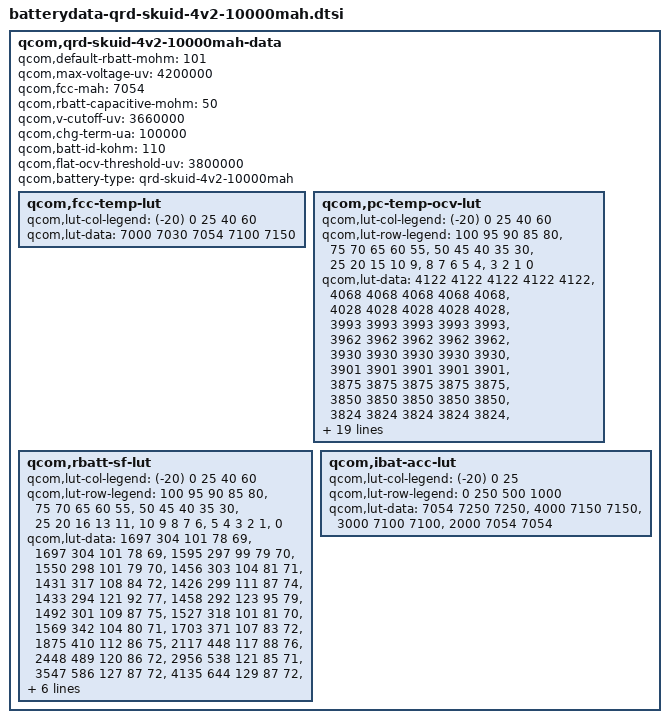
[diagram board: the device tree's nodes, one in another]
/* Copyright (c) 2014, The Linux Foundation. All rights reserved.
 *
 * This program is free software; you can redistribute it and/or modify
 * it under the terms of the GNU General Public License version 2 and
 * only version 2 as published by the Free Software Foundation.
 *
 * This program is distributed in the hope that it will be useful,
 * but WITHOUT ANY WARRANTY; without even the implied warranty of
 * MERCHANTABILITY or FITNESS FOR A PARTICULAR PURPOSE.  See the
 * GNU General Public License for more details.
 * Update from Qualcomm calibation data. 20150508.
 */


qcom,qrd-skuid-4v2-10000mah-data {
	qcom,default-rbatt-mohm = <101>;
	qcom,max-voltage-uv = <4200000>;
	qcom,fcc-mah = <7054>;
	qcom,rbatt-capacitive-mohm = <50>;
	qcom,v-cutoff-uv = <3660000>;
	qcom,chg-term-ua = <100000>;
	qcom,batt-id-kohm = <110>;
	qcom,flat-ocv-threshold-uv = <3800000>;
	qcom,battery-type = "qrd-skuid-4v2-10000mah";

	qcom,fcc-temp-lut {
		qcom,lut-col-legend = <(-20) 0 25 40 60>;
		qcom,lut-data = <7000 7030 7054 7100 7150>;
	};

	qcom,pc-temp-ocv-lut {
		qcom,lut-col-legend = <(-20) 0 25 40 60>;
		qcom,lut-row-legend = <100 95 90 85 80>,
				<75 70 65 60 55>,
				<50 45 40 35 30>,
				<25 20 15 10 9>,
				<8 7 6 5 4>,
				<3 2 1 0>;
		qcom,lut-data = <4122 4122 4122 4122 4122>,
			<4068 4068 4068 4068 4068>,
			<4028 4028 4028 4028 4028>,
			<3993 3993 3993 3993 3993>,
			<3962 3962 3962 3962 3962>,
			<3930 3930 3930 3930 3930>,
			<3901 3901 3901 3901 3901>,
			<3875 3875 3875 3875 3875>,
			<3850 3850 3850 3850 3850>,
			<3824 3824 3824 3824 3824>,
			<3799 3799 3799 3799 3799>,
			<3776 3776 3776 3776 3776>,
			<3755 3755 3755 3755 3755>,
			<3738 3738 3738 3738 3738>,
			<3724 3724 3724 3724 3724>,
			<3711 3711 3711 3711 3711>,
			<3700 3700 3700 3700 3700>,
			<3690 3690 3690 3690 3690>,
			<3681 3681 3681 3681 3681>,
			<3679 3679 3679 3679 3679>,
			<3678 3678 3678 3678 3678>,
			<3676 3676 3676 3676 3676>,
			<3674 3674 3674 3674 3674>,
			<3673 3673 3673 3673 3673>,
			<3671 3671 3671 3671 3671>,
			<3669 3669 3669 3669 3669>,
			<3667 3667 3667 3667 3667>,
			<3665 3665 3665 3665 3665>,
			<3664 3664 3664 3664 3664>;
	};

	qcom,rbatt-sf-lut {
		qcom,lut-col-legend = <(-20) 0 25 40 60>;
		qcom,lut-row-legend = <100 95 90 85 80>,
				<75 70 65 60 55>,
				<50 45 40 35 30>,
				<25 20 16 13 11>,
				<10 9 8 7 6>,
				<5 4 3 2 1>,
				<0>;
		qcom,lut-data = <1697 304 101 78 69>,
				<1697 304 101 78 69>,
				<1595 297 99  79 70>,
				<1550 298 101 79 70>,
				<1456 303 104 81 71>,
				<1431 317 108 84 72>,
				<1426 299 111 87 74>,
				<1433 294 121 92 77>,
				<1458 292 123 95 79>,
				<1492 301 109 87 75>,
				<1527 318 101 81 70>,
				<1569 342 104 80 71>,
				<1703 371 107 83 72>,
				<1875 410 112 86 75>,
				<2117 448 117 88 76>,
				<2448 489 120 86 72>,
				<2956 538 121 85 71>,
				<3547 586 127 87 72>,
				<4135 644 129 87 72>,
				<4497 677 129 87 72>,
				<4658 698 130 87 73>,
				<4972 733 134 89 75>,
				<5443 772 139 91 75>,
				<6052 821 145 93 77>,
				<6785 875 153 95 77>,
				<7687 939 160 96 77>,
				<8902 1023 163 95 75>,
				<10491 1162 168 96 75>,
				<12675 1403 183 100 77>,
				<15796 1861 210 107 81>,
				<22611 3723 396 195 93>;
	};

	qcom,ibat-acc-lut {
		qcom,lut-col-legend = <(-20) 0 25>;
		qcom,lut-row-legend = <0 250 500 1000>;
		
/*		过放, 放３Ｄ游戏会过放到３.３１Ｖ */
		qcom,lut-data = <7054 7250 7250>,
				<4000 7150 7150>,
				<3000 7100 7100>,
				<2000  7054 7054>;
				
/*		qcom,lut-data = <6054 6250 6250>,
				<4000 6150 6150>,
				<3000 6100 6100>,
				<2000  6054 6054>;
				*/
	};
};
